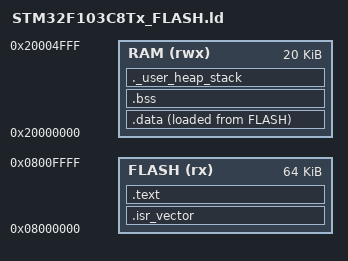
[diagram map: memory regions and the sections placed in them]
MEMORY
{
  FLASH (rx) : ORIGIN = 0x08000000, LENGTH = 64K
  RAM (rwx)  : ORIGIN = 0x20000000, LENGTH = 20K
}

ENTRY(Reset_Handler)

SECTIONS
{
  .isr_vector : { KEEP(*(.isr_vector)) } > FLASH
  .text : { *(.text*) *(.rodata*) } > FLASH
  _sidata = LOADADDR(.data);
  .data : {
    _sdata = .;
    *(.data*)
    _edata = .;
  } > RAM AT > FLASH
  .bss : {
    _sbss = .;
    *(.bss*) *(COMMON)
    _ebss = .;
  } > RAM
  ._user_heap_stack : {
    . = ALIGN(8);
    _end = .;
    . = . + 0x400;
    . = . + 0x400;
    . = ALIGN(8);
    _estack = ORIGIN(RAM) + LENGTH(RAM);
  } > RAM
}
